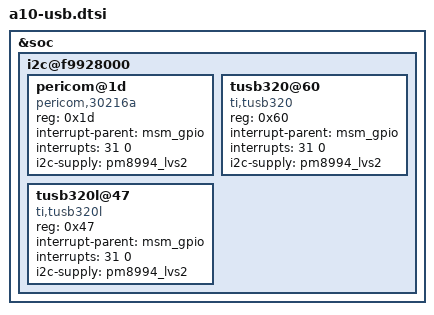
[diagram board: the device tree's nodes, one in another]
/* Copyright (c) 2017, The Linux Foundation. All rights reserved.
 *
 * This program is free software; you can redistribute it and/or modify
 * it under the terms of the GNU General Public License version 2 and
 * only version 2 as published by the Free Software Foundation.
 *
 * This program is distributed in the hope that it will be useful,
 * but WITHOUT ANY WARRANTY; without even the implied warranty of
 * MERCHANTABILITY or FITNESS FOR A PARTICULAR PURPOSE.  See the
 * GNU General Public License for more details.
 */

&soc {
	i2c@f9928000 { /* BLSP1 QUP6 */
		status = "ok";
		pericom@1d {
			compatible = "pericom,30216a";
			reg = <0x1d>;

			interrupt-parent = <&msm_gpio>;
			interrupts = <31 0>;

			i2c-supply = <&pm8994_lvs2>;
		};

		tusb320@60 {
			compatible = "ti,tusb320";
			reg = <0x60>;

			interrupt-parent = <&msm_gpio>;
			interrupts = <31 0>;

			i2c-supply = <&pm8994_lvs2>;
        };

		tusb320l@47 {
			compatible = "ti,tusb320l";
			reg = <0x47>;

			interrupt-parent = <&msm_gpio>;
			interrupts = <31 0>;

			i2c-supply = <&pm8994_lvs2>;
		};
	};	
};
